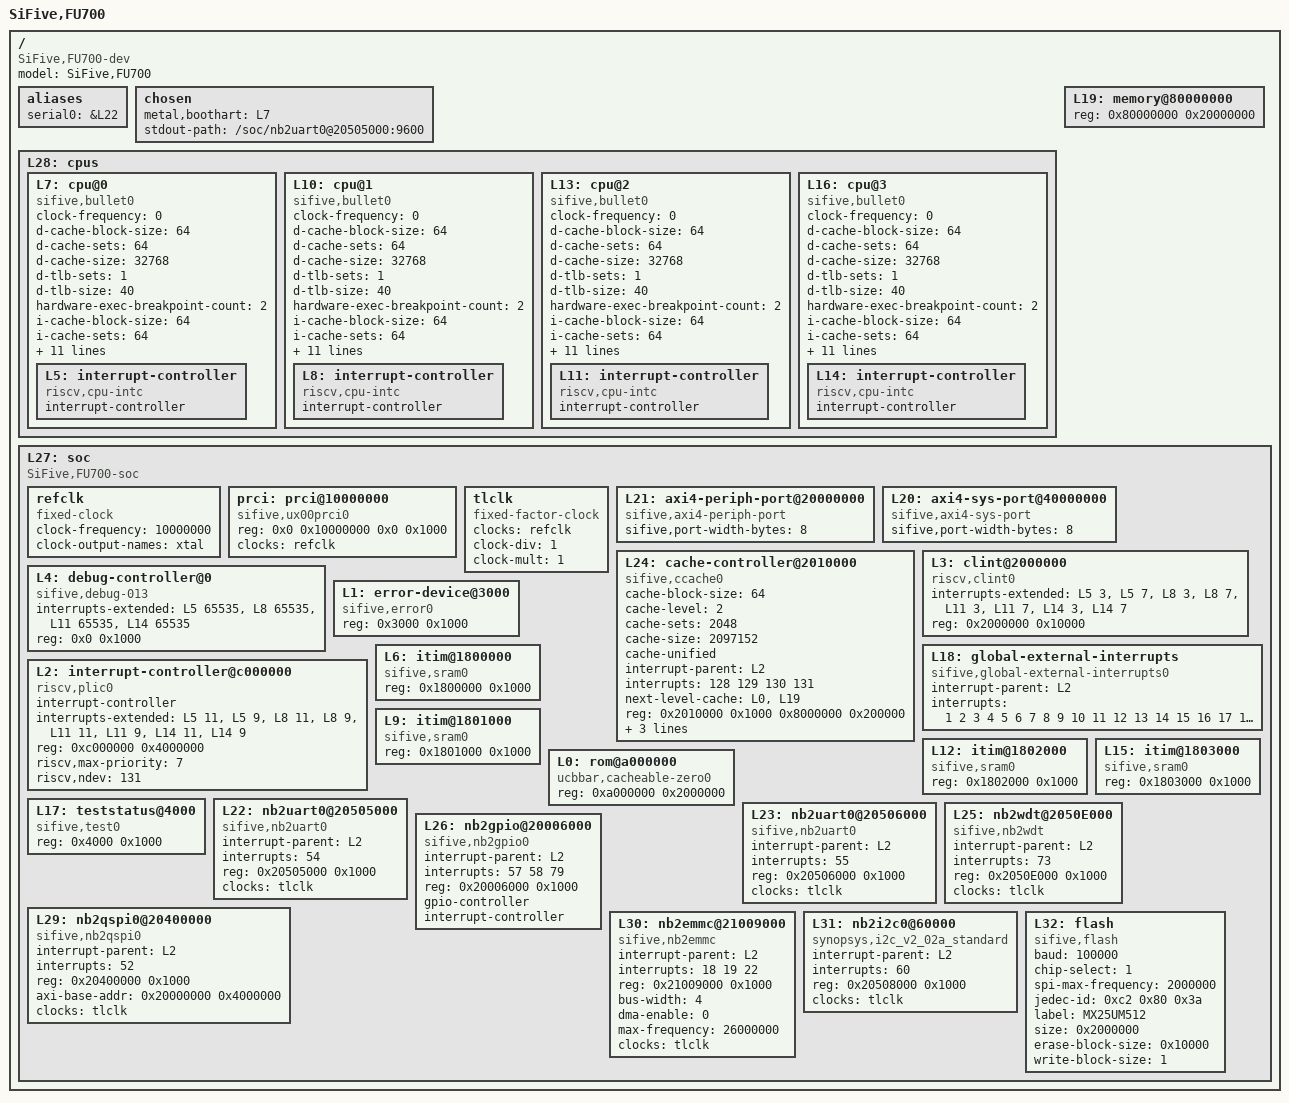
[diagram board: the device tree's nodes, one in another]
/dts-v1/;
/ {

	#address-cells = <1>;
	#size-cells = <1>;
	compatible = "SiFive,FU700-dev", "fu700-dev", "sifive-dev";
	model = "SiFive,FU700";

aliases {
		serial0 = &L22;
	};
chosen {
metal,boothart = <&L7>;
stdout-path = "/soc/nb2uart0@20505000:9600";
};
	L28: cpus {
		#address-cells = <1>;
		#size-cells = <0>;
		L7: cpu@0 {
			clock-frequency = <0>;
			compatible = "sifive,bullet0", "riscv";
			d-cache-block-size = <64>;
			d-cache-sets = <64>;
			d-cache-size = <32768>;
			d-tlb-sets = <1>;
			d-tlb-size = <40>;
			device_type = "cpu";
			hardware-exec-breakpoint-count = <2>;
			i-cache-block-size = <64>;
			i-cache-sets = <64>;
			i-cache-size = <32768>;
			i-tlb-sets = <1>;
			i-tlb-size = <40>;
			mmu-type = "riscv,sv39";
			next-level-cache = <&L24>;
			reg = <0x0>;
			riscv,isa = "rv64imafdc";
			riscv,pmpregions = <8>;
			sifive,itim = <&L6>;
			status = "okay";
			timebase-frequency = <1000000>;
			tlb-split;
			L5: interrupt-controller {
				#interrupt-cells = <1>;
				compatible = "riscv,cpu-intc";
				interrupt-controller;
			};
		};
		L10: cpu@1 {
			clock-frequency = <0>;
			compatible = "sifive,bullet0", "riscv";
			d-cache-block-size = <64>;
			d-cache-sets = <64>;
			d-cache-size = <32768>;
			d-tlb-sets = <1>;
			d-tlb-size = <40>;
			device_type = "cpu";
			hardware-exec-breakpoint-count = <2>;
			i-cache-block-size = <64>;
			i-cache-sets = <64>;
			i-cache-size = <32768>;
			i-tlb-sets = <1>;
			i-tlb-size = <40>;
			mmu-type = "riscv,sv39";
			next-level-cache = <&L24>;
			reg = <0x1>;
			riscv,isa = "rv64imafdc";
			riscv,pmpregions = <8>;
			sifive,itim = <&L9>;
			status = "okay";
			timebase-frequency = <1000000>;
			tlb-split;
			L8: interrupt-controller {
				#interrupt-cells = <1>;
				compatible = "riscv,cpu-intc";
				interrupt-controller;
			};
		};
		L13: cpu@2 {
			clock-frequency = <0>;
			compatible = "sifive,bullet0", "riscv";
			d-cache-block-size = <64>;
			d-cache-sets = <64>;
			d-cache-size = <32768>;
			d-tlb-sets = <1>;
			d-tlb-size = <40>;
			device_type = "cpu";
			hardware-exec-breakpoint-count = <2>;
			i-cache-block-size = <64>;
			i-cache-sets = <64>;
			i-cache-size = <32768>;
			i-tlb-sets = <1>;
			i-tlb-size = <40>;
			mmu-type = "riscv,sv39";
			next-level-cache = <&L24>;
			reg = <0x2>;
			riscv,isa = "rv64imafdc";
			riscv,pmpregions = <8>;
			sifive,itim = <&L12>;
			status = "okay";
			timebase-frequency = <1000000>;
			tlb-split;
			L11: interrupt-controller {
				#interrupt-cells = <1>;
				compatible = "riscv,cpu-intc";
				interrupt-controller;
			};
		};
		L16: cpu@3 {
			clock-frequency = <0>;
			compatible = "sifive,bullet0", "riscv";
			d-cache-block-size = <64>;
			d-cache-sets = <64>;
			d-cache-size = <32768>;
			d-tlb-sets = <1>;
			d-tlb-size = <40>;
			device_type = "cpu";
			hardware-exec-breakpoint-count = <2>;
			i-cache-block-size = <64>;
			i-cache-sets = <64>;
			i-cache-size = <32768>;
			i-tlb-sets = <1>;
			i-tlb-size = <40>;
			mmu-type = "riscv,sv39";
			next-level-cache = <&L24>;
			reg = <0x3>;
			riscv,isa = "rv64imafdc";
			riscv,pmpregions = <8>;
			sifive,itim = <&L15>;
			status = "okay";
			timebase-frequency = <1000000>;
			tlb-split;
			L14: interrupt-controller {
				#interrupt-cells = <1>;
				compatible = "riscv,cpu-intc";
				interrupt-controller;
			};
		};
	};
	L19: memory@80000000 {
		device_type = "memory";
		reg = <0x80000000 0x20000000>;
	};
	L27: soc {
		#address-cells = <1>;
		#size-cells = <1>;
		compatible = "SiFive,FU700-soc", "fu700-soc", "sifive-soc", "simple-bus";
		ranges;
		refclk: refclk {
			#clock-cells = <0>;
			compatible = "fixed-clock";
			clock-frequency = <10000000>;
			clock-output-names = "xtal";
		};
		prci: prci@10000000 {
			compatible = "sifive,ux00prci0";
			reg = <0x0 0x10000000 0x0 0x1000>;
			reg-names = "control";
			clocks = <&refclk>;
			#clock-cells = <1>;
		};
		tlclk: tlclk {
			compatible = "fixed-factor-clock";
			clocks = <&refclk>;
			#clock-cells = <0>;
			clock-div = <1>;
			clock-mult = <1>;
		};
		L21: axi4-periph-port@20000000 {
			#address-cells = <1>;
			#size-cells = <1>;
			compatible = "sifive,axi4-periph-port", "sifive,axi4-port", "sifive,periph-port", "simple-external-bus", "simple-bus";
			ranges = <0x20000000 0x20000000 0x20000000>;
			sifive,port-width-bytes = <8>;
		};
		L20: axi4-sys-port@40000000 {
			#address-cells = <1>;
			#size-cells = <1>;
			compatible = "sifive,axi4-sys-port", "sifive,axi4-port", "sifive,sys-port", "simple-external-bus", "simple-bus";
			ranges = <0x40000000 0x40000000 0x20000000>;
			sifive,port-width-bytes = <8>;
		};
		L24: cache-controller@2010000 {
			cache-block-size = <64>;
			cache-level = <2>;
			cache-sets = <2048>;
			cache-size = <2097152>;
			cache-unified;
			compatible = "sifive,ccache0", "cache";
			interrupt-parent = <&L2>;
			interrupts = <128 129 130 131>;
			next-level-cache = <&L0 &L19>;
			reg = <0x2010000 0x1000 0x8000000 0x200000>;
			reg-names = "control", "sideband";
			sifive,a-mshr-count = <12>;
			sifive,bank-count = <4>;
			sifive,ecc-granularity = <8>;
		};
		L3: clint@2000000 {
			compatible = "riscv,clint0";
			interrupts-extended = <&L5 3 &L5 7 &L8 3 &L8 7 &L11 3 &L11 7 &L14 3 &L14 7>;
			reg = <0x2000000 0x10000>;
			reg-names = "control";
		};
		L4: debug-controller@0 {
			compatible = "sifive,debug-013", "riscv,debug-013";
			interrupts-extended = <&L5 65535 &L8 65535 &L11 65535 &L14 65535>;
			reg = <0x0 0x1000>;
			reg-names = "control";
		};
		L1: error-device@3000 {
			compatible = "sifive,error0";
			reg = <0x3000 0x1000>;
		};
		L18: global-external-interrupts {
			compatible = "sifive,global-external-interrupts0";
			interrupt-parent = <&L2>;
			interrupts = <1 2 3 4 5 6 7 8 9 10 11 12 13 14 15 16 17 18 19 20 21 22 23 24 25 26 27 28 29 30 31 32 33 34 35 36 37 38 39 40 41 42 43 44 45 46 47 48 49 50 51 52 53 54 55 56 57 58 59 60 61 62 63 64 65 66 67 68 69 70 71 72 73 74 75 76 77 78 79 80 81 82 83 84 85 86 87 88 89 90 91 92 93 94 95 96 97 98 99 100 101 102 103 104 105 106 107 108 109 110 111 112 113 114 115 116 117 118 119 120 121 122 123 124 125 126 127>;
		};
		L2: interrupt-controller@c000000 {
			#interrupt-cells = <1>;
			compatible = "riscv,plic0";
			interrupt-controller;
			interrupts-extended = <&L5 11 &L5 9 &L8 11 &L8 9 &L11 11 &L11 9 &L14 11 &L14 9>;
			reg = <0xc000000 0x4000000>;
			reg-names = "control";
			riscv,max-priority = <7>;
			riscv,ndev = <131>;
		};
		L6: itim@1800000 {
			compatible = "sifive,sram0";
			reg = <0x1800000 0x1000>;
			reg-names = "mem";
		};
		L9: itim@1801000 {
			compatible = "sifive,sram0";
			reg = <0x1801000 0x1000>;
			reg-names = "mem";
		};
		L12: itim@1802000 {
			compatible = "sifive,sram0";
			reg = <0x1802000 0x1000>;
			reg-names = "mem";
		};
		L15: itim@1803000 {
			compatible = "sifive,sram0";
			reg = <0x1803000 0x1000>;
			reg-names = "mem";
		};
		L0: rom@a000000 {
			compatible = "ucbbar,cacheable-zero0";
			reg = <0xa000000 0x2000000>;
		};


		L17: teststatus@4000 {
			compatible = "sifive,test0";
			reg = <0x4000 0x1000>;
			reg-names = "control";
		};
		L22: nb2uart0@20505000 {
                        compatible = "sifive,nb2uart0";
                        interrupt-parent = <&L2>;
                        interrupts = <54>;
                        reg = <0x20505000 0x1000>;
                        reg-names = "control";
                        clocks = <&tlclk>;
                };
		L23: nb2uart0@20506000 {
			compatible = "sifive,nb2uart0";
			interrupt-parent = <&L2>;
			interrupts = <55>;
			reg = <0x20506000 0x1000>;
			reg-names = "control";
			clocks = <&tlclk>;
		};
		L25: nb2wdt@2050E000 {
                        compatible = "sifive,nb2wdt";
                        interrupt-parent = <&L2>;
                        interrupts = <73>;
                        reg = <0x2050E000 0x1000>;
                        reg-names = "control";
                        clocks = <&tlclk>;
                };
		L26: nb2gpio@20006000 {
                        compatible = "sifive,nb2gpio0";
                        interrupt-parent = <&L2>;
                        interrupts = <57 58 79>;
                        reg = <0x20006000 0x1000>;
                        reg-names = "control";
                        gpio-controller;
//                        #gpio-cells = <2>;
                        interrupt-controller;
		};
		L29: nb2qspi0@20400000 {
                         compatible = "sifive,nb2qspi0";
                         interrupt-parent = <&L2>;
                         interrupts = <52>;
                         reg = <0x20400000 0x1000>;
			 axi-base-addr=<0x20000000 0x4000000>;
                         reg-names = "control";
                         clocks = <&tlclk>;
                 }; 
		L30: nb2emmc@21009000{
			compatible = "sifive,nb2emmc";
			interrupt-parent = <&L2>;
			interrupts = <18 19 22>;
			reg = <0x21009000 0x1000>;
			bus-width =<4>;
			dma-enable =<0>;
			max-frequency = <26000000>;
			reg-names = "mem";
			clocks = <&tlclk>;
		};
		L31: nb2i2c0@60000{
			compatible = "synopsys,i2c_v2_02a_standard";
			interrupt-parent = <&L2>;
			interrupts = <60>;
			reg = <0x20508000 0x1000>;
			reg-names = "control";
			clocks = <&tlclk>;
		};
		L32: flash{
			compatible = "sifive,flash";
			baud = <100000>;
			chip-select = <1>;
			spi-max-frequency = <2000000>;
                        jedec-id = <0xc2 0x80 0x3a>;
			label = "MX25UM512";
			size = <0x2000000>;
                        erase-block-size = <0x10000>;
                        write-block-size = <1>;
		};
	};
};

